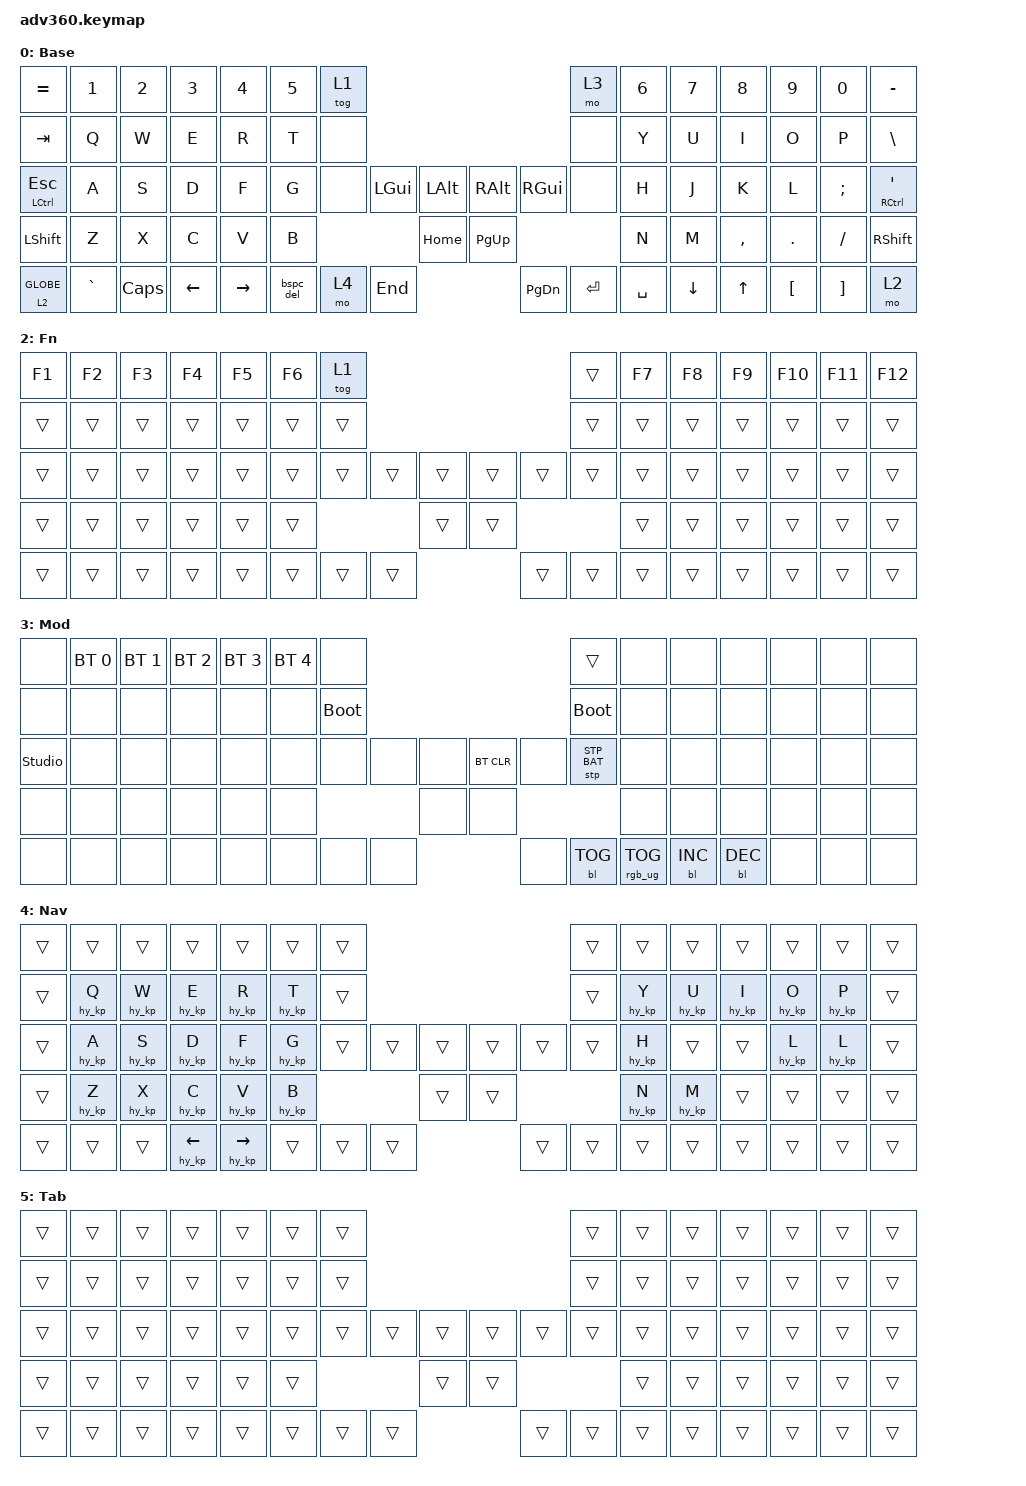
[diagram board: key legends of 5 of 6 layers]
/*
 * Copyright (c) 2020 The ZMK Contributors
 *
 * SPDX-License-Identifier: MIT
 */
/* THIS FILE WAS GENERATED!
 *
 * This file was generated automatically. You may or may not want to
 * edit it directly.
 */

#include <behaviors.dtsi>
#include "keypos_adv360.h"
#include <dt-bindings/zmk/backlight.h>
#include <dt-bindings/zmk/bt.h>
#include <dt-bindings/zmk/keys.h>
#include <dt-bindings/zmk/rgb.h>
#include <dt-bindings/zmk/stp.h>
#include <dt-bindings/zmk/backlight.h>
#include <dt-bindings/zmk/pointing.h>

// https://zmk.dev/docs/behaviors/caps-word
&caps_word {
    continue-list = <UNDERSCORE MINUS>;
};

/ {
    behaviors {
        #include "macros.dtsi"

        // shift + backspace triggers delete
        bspc_del: backspace_delete {
            compatible = "zmk,behavior-mod-morph";
            #binding-cells = <0>;
            bindings =
                <&kp BACKSPACE>,
                <&kp DELETE>;

            mods = <(MOD_LSFT|MOD_RSFT)>;
            keep-mods = <(MOD_RSFT)>;
        };

        // Swapper for smart alt+tab

        /* at_f: application_toggle_forward { */
        /*     compatible = "zmk,behavior-tri-state"; */
        /*     label = "APPLICATION_TOGGLE"; */
        /*     #binding-cells = <0>; */
        /*     bindings = */
        /*         <&kt LGUI>, */
        /*         <&kp TAB>, */
        /*         <&kt LGUI>; */

        /*     ignored-key-positions = <46 42>; */
        /* }; */
        /* at_b: application_toggle_back { */
        /*     compatible = "zmk,behavior-tri-state"; */
        /*     label = "APPLICATION_TOGGLE_BACK"; */
        /*     #binding-cells = <0>; */
        /*     bindings = */
        /*         <&kt LGUI>, */
        /*         <&kp LS(TAB)>, */
        /*         <&kt LGUI>; */

        /*     ignored-key-positions = <54>; */
        /* }; */

        hml: homerow_mods_l {
          compatible = "zmk,behavior-hold-tap";
          #binding-cells = <2>;
          bindings = <&kp>, <&kp>;
          flavor = "balanced";
          tapping-term-ms = <280>;
          quick_tap_ms = <175>;
          require-prior-idle-ms = <150>;
          hold-trigger-key-positions = <KEYS_R THUMBS_LEFT THUMBS_RIGHT>;
          hold-trigger-on-release;             // delay positional check until key-release
          // global-quick-tap;
          // retro-tap;
        };

        hmr: homerow_mods_r {
          compatible = "zmk,behavior-hold-tap";
          #binding-cells = <2>;
          bindings = <&kp>, <&kp>;
          flavor = "balanced";
          tapping-term-ms = <280>;
          quick_tap_ms = <175>;
          require-prior-idle-ms = <150>;
          hold-trigger-key-positions = <KEYS_L THUMBS_LEFT THUMBS_RIGHT>;
          hold-trigger-on-release;             // delay positional check until key-release
          // global-quick-tap;
          // retro-tap;
        };
    };

    combos {
        compatible = "zmk,combos";

        // pressing both shift keys enables caps_word
        combo_caps {
            timeout-ms = <50>;
            key-positions = <46 59>;
            bindings = <&caps_word>;
        };
    };

    macros {
        compatible = "zmk,macros";

        hyper: hyper {
            compatible = "zmk,behavior-macro";
            label = "HYPER";
            #binding-cells = <0>;
            bindings = <&kp LCTRL &kp LSHFT &kp LALT &kp LGUI>;
        };

        meh: meh {
            compatible = "zmk,behavior-macro";
            label = "HYPER";
            #binding-cells = <0>;
            bindings = <&kp LCTRL &kp LSHFT &kp LALT>;
        };

        hy_kp: hy_kp {
            compatible = "zmk,behavior-macro-one-param";
            label = "HYPER";
            #binding-cells = <1>;
            bindings = <&kp LCTRL &kp LSHFT &kp LALT &kp LGUI>;
        };

        meh_kp: meh_kp {
            compatible = "zmk,behavior-macro-one-param";
            label = "MEH";
            #binding-cells = <1>;
            bindings = <&kp LCTRL &kp LSHFT &kp LALT>;
        };
    };

    keymap {
        compatible = "zmk,keymap";

        default_layer {
            display-name = "Base";
            bindings = <
&kp EQUAL      &kp N1     &kp N2    &kp N3    &kp N4     &kp N5  &tog 1                                                   &mo 3      &kp N6  &kp N7    &kp N8     &kp N9    &kp N0    &kp MINUS
&kp TAB        &kp Q      &kp W     &kp E     &kp R      &kp T   &none                                                    &none      &kp Y   &kp U     &kp I      &kp O     &kp P     &kp BSLH
&mt LCTRL ESC  &kp A      &kp S     &kp D     &kp F      &kp G   &none      &kp LGUI  &kp LALT      &kp RALT   &kp RGUI   &none      &kp H   &kp J     &kp K      &kp L     &kp SEMI  &mt RCTRL SQT
&kp LSHFT      &kp Z      &kp X     &kp C     &kp V      &kp B                        &kp HOME      &kp PG_UP                        &kp N   &kp M     &kp COMMA  &kp DOT   &kp FSLH  &kp RSHFT
&lt 2 GLOBE       &kp GRAVE  &kp CAPS  &kp LEFT  &kp RIGHT          &bspc_del  &mo 4     &kp END       &kp PG_DN  &kp ENTER  &kp SPACE          &kp DOWN  &kp UP     &kp LBKT  &kp RBKT  &mo 2
            >;
        };

        keypad {
            display-name = "Kp";
            bindings = <
&trans  &trans  &trans  &trans  &trans  &trans  &trans                                      &trans  &trans  &kp KP_NUM  &kp KP_EQUAL  &kp KP_DIVIDE  &kp KP_MULTIPLY  &trans
&trans  &trans  &trans  &trans  &trans  &trans  &trans                                      &trans  &trans  &kp KP_N7   &kp KP_N8     &kp KP_N9      &kp KP_MINUS     &trans
&trans  &trans  &trans  &trans  &trans  &trans  &trans  &trans  &trans      &trans  &trans  &trans  &trans  &kp KP_N4   &kp KP_N5     &kp KP_N6      &kp KP_PLUS      &trans
&trans  &trans  &trans  &trans  &trans  &trans                  &trans      &trans                  &trans  &kp KP_N1   &kp KP_N2     &kp KP_N3      &kp KP_ENTER     &trans
&trans  &trans  &trans  &trans  &trans          &trans  &trans  &trans      &trans  &trans  &trans          &trans      &trans        &trans         &trans
            >;
        };

        fn {
            display-name = "Fn";
            bindings = <
&kp F1  &kp F2     &kp F3    &kp F4    &kp F5     &kp F6  &tog 1                                      &trans  &kp F7  &kp F8     &kp F9    &kp F10   &kp F11    &kp F12
&trans  &trans     &trans    &trans    &trans     &trans  &trans                                      &trans  &trans  &trans     &trans    &trans    &trans     &trans
&trans  &trans     &trans    &trans    &trans     &trans  &trans  &trans  &trans      &trans  &trans  &trans  &trans  &trans     &trans    &trans    &trans     &trans
&trans  &trans     &trans    &trans    &trans     &trans                  &trans      &trans                  &trans  &trans     &trans    &trans    &trans     &trans
&trans  &trans     &trans    &trans    &trans             &trans  &trans  &trans      &trans  &trans  &trans          &trans     &trans    &trans    &trans     &trans
            >;
        };

        mod {
            display-name = "Mod";
            bindings = <
&none           &bt BT_SEL 0  &bt BT_SEL 1  &bt BT_SEL 2  &bt BT_SEL 3  &bt BT_SEL 4  &none                                                  &trans                  &none  &none       &none       &none  &none  &none
&none           &none         &none         &none         &none         &none         &bootloader                                            &bootloader             &none  &none       &none       &none  &none  &none
&studio_unlock  &none         &none         &none         &none         &none         &none        &none  &none      &bt BT_CLR  &none       &stp STP_BAT            &none  &none       &none       &none  &none  &none
&none           &none         &none         &none         &none         &none                             &none      &none                                           &none  &none       &none       &none  &none  &none
&none           &none         &none         &none         &none                       &none        &none  &none      &none       &bl BL_TOG  &rgb_ug RGB_TOG                &bl BL_INC  &bl BL_DEC  &none  &none  &none
            >;
        };

        nav {
            display-name = "Nav";
            bindings = <
&trans  &trans                 &trans                 &trans                 &trans                 &trans                 &trans                                      &trans  &trans                 &trans                 &trans                 &trans                 &trans                 &trans
&trans  &hy_kp Q               &hy_kp W               &hy_kp E               &hy_kp R               &hy_kp T               &trans                                      &trans  &hy_kp Y               &hy_kp U               &hy_kp I               &hy_kp O               &hy_kp P               &trans
&trans  &hy_kp A               &hy_kp S               &hy_kp D               &hy_kp F               &hy_kp G               &trans  &trans  &trans      &trans  &trans  &trans  &hy_kp H               &trans                 &trans                 &hy_kp L               &hy_kp L               &trans
&trans  &hy_kp Z               &hy_kp X               &hy_kp C               &hy_kp V               &hy_kp B                               &trans      &trans                  &hy_kp N               &hy_kp M               &trans                 &trans                 &trans                 &trans
&trans  &trans                 &trans                 &hy_kp LEFT            &hy_kp RIGHT                                  &trans  &trans  &trans      &trans  &trans  &trans                         &trans                 &trans                 &trans                 &trans                 &trans
            >;
        };

        tab {
            display-name = "Tab";
            bindings = <
&trans  &trans  &trans  &trans  &trans  &trans  &trans                                      &trans  &trans  &trans  &trans  &trans  &trans  &trans
&trans  &trans  &trans  &trans  &trans  &trans  &trans                                      &trans  &trans  &trans  &trans  &trans  &trans  &trans
&trans  &trans  &trans  &trans  &trans  &trans  &trans  &trans  &trans      &trans  &trans  &trans  &trans  &trans  &trans  &trans  &trans  &trans
&trans  &trans  &trans  &trans  &trans  &trans                  &trans      &trans                  &trans  &trans  &trans  &trans  &trans  &trans
&trans  &trans  &trans  &trans  &trans          &trans  &trans  &trans      &trans  &trans  &trans          &trans  &trans  &trans  &trans  &trans
            >;
        };
    };
};

// vim: set ft=c shiftwidth=4 tabstop=4 expandtab:
